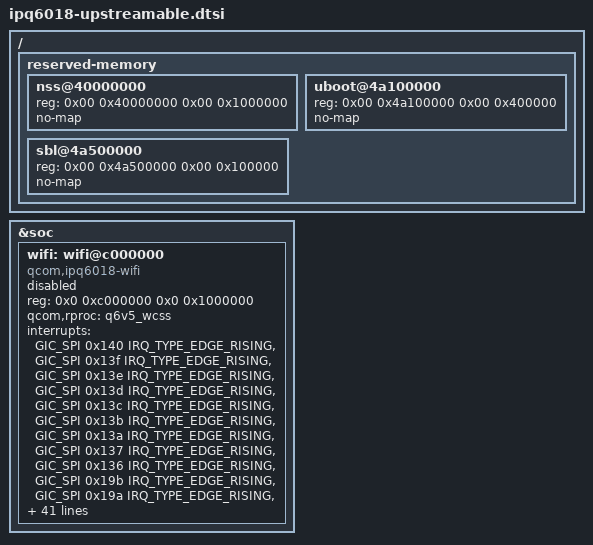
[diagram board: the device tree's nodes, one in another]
/ {
	reserved-memory {
		#address-cells = <2>;
		#size-cells = <2>;
		ranges;

		nss@40000000 {
			reg = <0x00 0x40000000 0x00 0x1000000>;
			no-map;
		};

		uboot@4a100000 {
			reg = <0x00 0x4a100000 0x00 0x400000>;
			no-map;
		};

		sbl@4a500000 {
			reg = <0x00 0x4a500000 0x00 0x100000>;
			no-map;
		};
	};
};

&soc {
	wifi: wifi@c000000 {
		compatible = "qcom,ipq6018-wifi";
		reg = <0x0 0xc000000 0x0 0x1000000>;
		qcom,rproc = <&q6v5_wcss>;
		interrupts = <GIC_SPI 0x140 IRQ_TYPE_EDGE_RISING>,
			     <GIC_SPI 0x13f IRQ_TYPE_EDGE_RISING>,
			     <GIC_SPI 0x13e IRQ_TYPE_EDGE_RISING>,
			     <GIC_SPI 0x13d IRQ_TYPE_EDGE_RISING>,
			     <GIC_SPI 0x13c IRQ_TYPE_EDGE_RISING>,
			     <GIC_SPI 0x13b IRQ_TYPE_EDGE_RISING>,
			     <GIC_SPI 0x13a IRQ_TYPE_EDGE_RISING>,
			     <GIC_SPI 0x137 IRQ_TYPE_EDGE_RISING>,
			     <GIC_SPI 0x136 IRQ_TYPE_EDGE_RISING>,
			     <GIC_SPI 0x19b IRQ_TYPE_EDGE_RISING>,
			     <GIC_SPI 0x19a IRQ_TYPE_EDGE_RISING>,
			     <GIC_SPI 0x28 IRQ_TYPE_EDGE_RISING>,
			     <GIC_SPI 0x27 IRQ_TYPE_EDGE_RISING>,
			     <GIC_SPI 0x12e IRQ_TYPE_EDGE_RISING>,
			     <GIC_SPI 0x12d IRQ_TYPE_EDGE_RISING>,
			     <GIC_SPI 0x25 IRQ_TYPE_EDGE_RISING>,
			     <GIC_SPI 0x24 IRQ_TYPE_EDGE_RISING>,
			     <GIC_SPI 0x128 IRQ_TYPE_EDGE_RISING>,
			     <GIC_SPI 0x127 IRQ_TYPE_EDGE_RISING>,
			     <GIC_SPI 0x126 IRQ_TYPE_EDGE_RISING>,
			     <GIC_SPI 0x125 IRQ_TYPE_EDGE_RISING>,
			     <GIC_SPI 0x124 IRQ_TYPE_EDGE_RISING>,
			     <GIC_SPI 0x123 IRQ_TYPE_EDGE_RISING>,
			     <GIC_SPI 0x122 IRQ_TYPE_EDGE_RISING>,
			     <GIC_SPI 0x121 IRQ_TYPE_EDGE_RISING>,
			     <GIC_SPI 0x120 IRQ_TYPE_EDGE_RISING>,
			     <GIC_SPI 0xef IRQ_TYPE_EDGE_RISING>,
			     <GIC_SPI 0xec IRQ_TYPE_EDGE_RISING>,
			     <GIC_SPI 0xeb IRQ_TYPE_EDGE_RISING>,
			     <GIC_SPI 0xea IRQ_TYPE_EDGE_RISING>,
			     <GIC_SPI 0xe9 IRQ_TYPE_EDGE_RISING>,
			     <GIC_SPI 0xe8 IRQ_TYPE_EDGE_RISING>,
			     <GIC_SPI 0xe7 IRQ_TYPE_EDGE_RISING>,
			     <GIC_SPI 0xe6 IRQ_TYPE_EDGE_RISING>,
			     <GIC_SPI 0xe5 IRQ_TYPE_EDGE_RISING>,
			     <GIC_SPI 0xe4 IRQ_TYPE_EDGE_RISING>,
			     <GIC_SPI 0xe0 IRQ_TYPE_EDGE_RISING>,
			     <GIC_SPI 0xdf IRQ_TYPE_EDGE_RISING>,
			     <GIC_SPI 0xcb IRQ_TYPE_EDGE_RISING>,
			     <GIC_SPI 0xb7 IRQ_TYPE_EDGE_RISING>,
			     <GIC_SPI 0xb4 IRQ_TYPE_EDGE_RISING>,
			     <GIC_SPI 0xb3 IRQ_TYPE_EDGE_RISING>,
			     <GIC_SPI 0xb2 IRQ_TYPE_EDGE_RISING>,
			     <GIC_SPI 0xb1 IRQ_TYPE_EDGE_RISING>,
			     <GIC_SPI 0xb0 IRQ_TYPE_EDGE_RISING>,
			     <GIC_SPI 0xa3 IRQ_TYPE_EDGE_RISING>,
			     <GIC_SPI 0xa2 IRQ_TYPE_EDGE_RISING>,
			     <GIC_SPI 0xa0 IRQ_TYPE_EDGE_RISING>,
			     <GIC_SPI 0x9f IRQ_TYPE_EDGE_RISING>,
			     <GIC_SPI 0x9e IRQ_TYPE_EDGE_RISING>,
			     <GIC_SPI 0x9d IRQ_TYPE_EDGE_RISING>,
			     <GIC_SPI 0x9c IRQ_TYPE_EDGE_RISING>;
		interrupt-names = "misc-pulse1", "misc-latch", "sw-exception",
				  "watchdog", "ce0", "ce1", "ce2", "ce3", "ce4",
				  "ce5", "ce6", "ce7", "ce8", "ce9", "ce10",
				  "ce11", "host2wbm-desc-feed",
				  "host2reo-re-injection", "host2reo-command",
				  "host2rxdma-monitor-ring3",
				  "host2rxdma-monitor-ring2",
				  "host2rxdma-monitor-ring1",
				  "reo2ost-exception", "wbm2host-rx-release",
				  "reo2host-status",
				  "reo2host-destination-ring4",
				  "reo2host-destination-ring3",
				  "reo2host-destination-ring2",
				  "reo2host-destination-ring1",
				  "rxdma2host-monitor-destination-mac3",
				  "rxdma2host-monitor-destination-mac2",
				  "rxdma2host-monitor-destination-mac1",
				  "ppdu-end-interrupts-mac3",
				  "ppdu-end-interrupts-mac2",
				  "ppdu-end-interrupts-mac1",
				  "rxdma2host-monitor-status-ring-mac3",
				  "rxdma2host-monitor-status-ring-mac2",
				  "rxdma2host-monitor-status-ring-mac1",
				  "host2rxdma-host-buf-ring-mac3",
				  "host2rxdma-host-buf-ring-mac2",
				  "host2rxdma-host-buf-ring-mac1",
				  "rxdma2host-destination-ring-mac3",
				  "rxdma2host-destination-ring-mac2",
				  "rxdma2host-destination-ring-mac1",
				  "host2tcl-input-ring4",
				  "host2tcl-input-ring3",
				  "host2tcl-input-ring2",
				  "host2tcl-input-ring1",
				  "wbm2host-tx-completions-ring3",
				  "wbm2host-tx-completions-ring2",
				  "wbm2host-tx-completions-ring1",
				  "tcl2host-status-ring";
		status = "disabled";
	};
};
